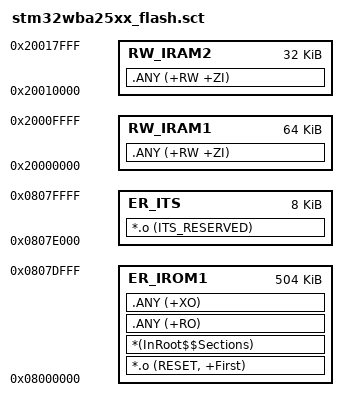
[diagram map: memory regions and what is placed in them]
; *************************************************************
; *** Scatter-Loading Description File generated by uVision ***
; *************************************************************

LR_IROM1 0x08000000 0x0007E000  {    ; load region size_region
  ER_IROM1 0x08000000 0x0007E000  {  ; load address = execution address
   *.o (RESET, +First)
   *(InRoot$$Sections)
   .ANY (+RO)
   .ANY (+XO)
  }

  RW_IRAM1 0x20000000 0x00010000  {  ; RW data
   .ANY (+RW +ZI)
  }
  RW_IRAM2 0x20010000 0x00008000  {  ; RW data
   .ANY (+RW +ZI)
  }
}

LR_ITS 0x0807E000 0x2000  {  ; Separate load region for ITS
  ER_ITS 0x0807E000 0x2000  {  ; load address = execution address
   *.o (ITS_RESERVED)
  }
}
